VERSION ""

NS_ :

BS_:

BU_: XXX

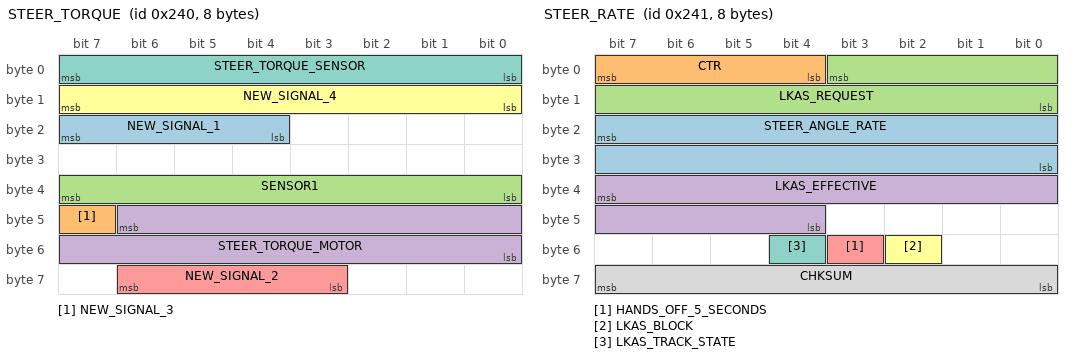
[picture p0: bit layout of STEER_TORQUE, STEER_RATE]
BO_ 576 STEER_TORQUE: 8 XXX
 SG_ NEW_SIGNAL_1 : 23|4@0+ (1,0) [0|255] "" XXX
 SG_ NEW_SIGNAL_3 : 47|1@0+ (1,0) [0|1] "" XXX
 SG_ SENSOR1 : 39|8@0+ (1,-128) [0|127] "" XXX
 SG_ STEER_TORQUE_MOTOR : 46|15@0- (0.1,0) [-3000|3000] "tbd" XXX
 SG_ NEW_SIGNAL_2 : 62|4@0+ (1,0) [0|31] "" XXX
 SG_ NEW_SIGNAL_4 : 15|8@0+ (1,0) [0|127] "" XXX
 SG_ STEER_TORQUE_SENSOR : 7|8@0+ (1,-127) [-85|85] "" XXX

BO_ 577 STEER_RATE: 8 XXX
 SG_ STEER_ANGLE_RATE : 23|16@0+ (0.25,-8192) [0|1] "deg/s" XXX
 SG_ CTR : 7|4@0+ (1,0) [0|15] "" XXX
 SG_ LKAS_REQUEST : 3|12@0+ (1,-2048) [0|15] "" XXX
 SG_ LKAS_EFFECTIVE : 39|12@0+ (1,-2048) [0|255] "" XXX
 SG_ HANDS_OFF_5_SECONDS : 51|1@0+ (1,0) [0|1] "" XXX
 SG_ LKAS_BLOCK : 50|1@1+ (1,0) [0|3] "" XXX
 SG_ LKAS_TRACK_STATE : 52|1@0+ (1,0) [0|3] "" XXX
 SG_ CHKSUM : 63|8@0+ (1,0) [0|255] "" XXX

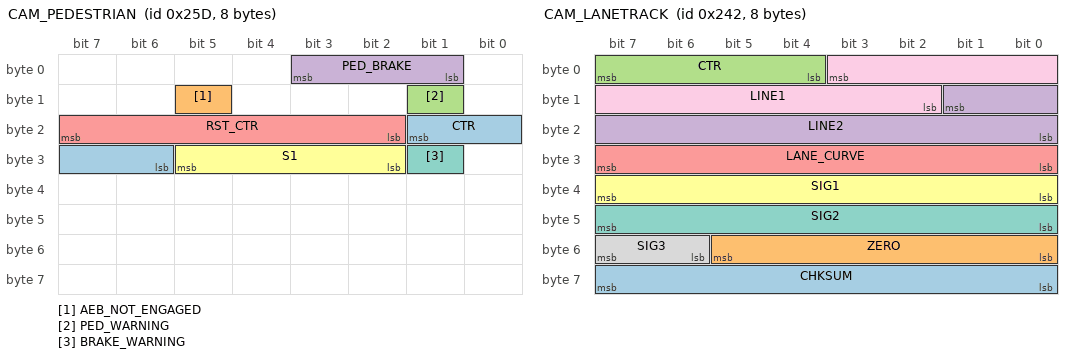
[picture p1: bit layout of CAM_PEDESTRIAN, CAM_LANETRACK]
BO_ 605 CAM_PEDESTRIAN: 8 XXX
 SG_ CTR : 17|4@0+ (1,0) [0|255] "" XXX
 SG_ AEB_NOT_ENGAGED : 13|1@0+ (1,0) [0|1] "" XXX
 SG_ PED_WARNING : 9|1@0+ (1,0) [0|255] "" XXX
 SG_ PED_BRAKE : 3|3@0+ (1,0) [0|7] "" XXX
 SG_ RST_CTR : 23|6@0+ (1,0) [0|63] "" XXX
 SG_ S1 : 29|4@0+ (1,0) [0|31] "" XXX
 SG_ BRAKE_WARNING : 25|1@0+ (1,0) [0|1] "" XXX

BO_ 578 CAM_LANETRACK: 8 XXX
 SG_ CHKSUM : 63|8@0+ (1,0) [0|255] "" XXX
 SG_ ZERO : 53|6@0+ (1,0) [0|63] "" XXX
 SG_ CTR : 7|4@0+ (1,0) [0|15] "" XXX
 SG_ LINE2 : 9|10@0+ (1,-686) [0|255] "" XXX
 SG_ LANE_CURVE : 31|8@0+ (1,-127) [0|255] "" XXX
 SG_ SIG1 : 39|8@0+ (1,-128) [0|255] "" XXX
 SG_ SIG2 : 47|8@0+ (1,0) [0|255] "" XXX
 SG_ SIG3 : 55|2@0+ (1,0) [0|3] "" XXX
 SG_ LINE1 : 3|10@0+ (1,-686) [0|1] "" XXX

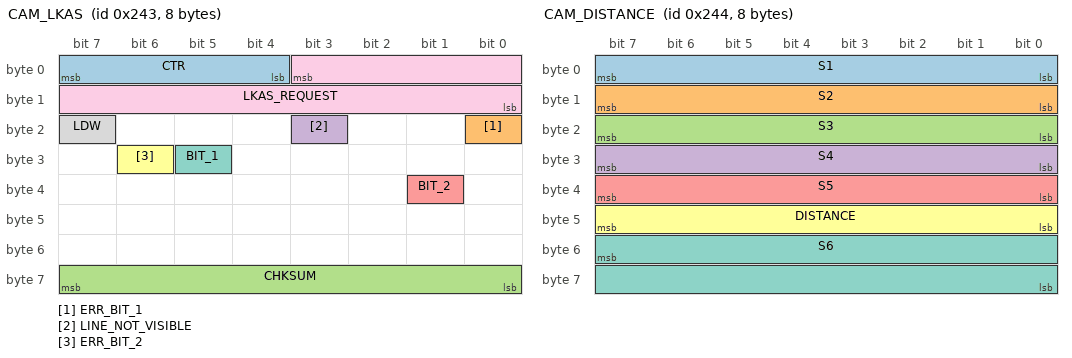
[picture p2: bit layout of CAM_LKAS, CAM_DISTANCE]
BO_ 579 CAM_LKAS: 8 XXX
 SG_ CTR : 7|4@0+ (1,0) [0|15] "" XXX
 SG_ ERR_BIT_1 : 16|1@0+ (1,0) [0|1] "" XXX
 SG_ CHKSUM : 63|8@0+ (1,0) [0|15] "" XXX
 SG_ LINE_NOT_VISIBLE : 19|1@0+ (1,0) [0|1] "" XXX
 SG_ BIT_2 : 33|1@0+ (1,0) [0|1] "" XXX
 SG_ ERR_BIT_2 : 30|1@0+ (1,0) [0|1] "" XXX
 SG_ BIT_1 : 29|1@0+ (1,0) [0|1] "" XXX
 SG_ LDW : 23|1@0+ (1,0) [0|1] "" XXX
 SG_ LKAS_REQUEST : 3|12@0+ (1,-2048) [0|2048] "" XXX

BO_ 580 CAM_DISTANCE: 8 XXX
 SG_ S1 : 0|8@1+ (1,0) [0|127] "" XXX
 SG_ S2 : 15|8@0+ (1,0) [0|1] "" XXX
 SG_ S3 : 16|8@1+ (1,0) [0|3] "" XXX
 SG_ S4 : 24|8@1+ (1,0) [0|31] "" XXX
 SG_ S5 : 32|8@1+ (1,0) [0|255] "" XXX
 SG_ DISTANCE : 47|8@0+ (1,0) [0|65535] "" XXX
 SG_ S6 : 55|16@0+ (1,0) [0|255] "" XXX

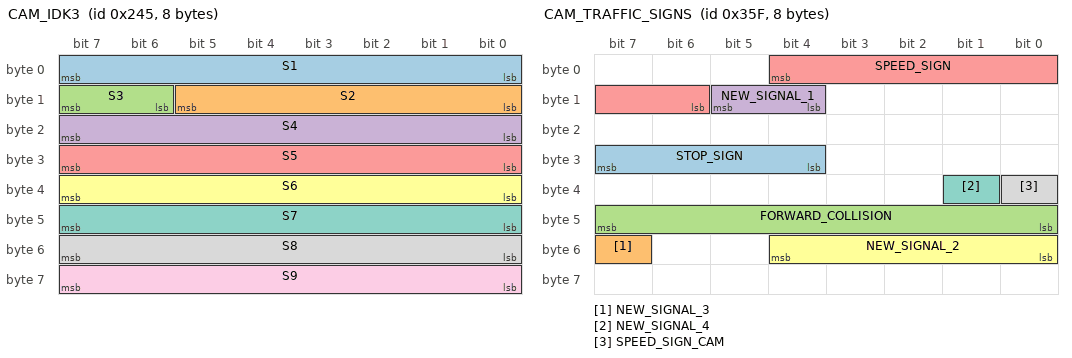
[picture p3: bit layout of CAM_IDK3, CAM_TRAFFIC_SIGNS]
BO_ 581 CAM_IDK3: 8 XXX
 SG_ S1 : 0|8@1+ (1,0) [0|15] "" XXX
 SG_ S2 : 8|6@1+ (1,0) [0|255] "" XXX
 SG_ S3 : 15|2@0+ (1,0) [0|3] "" XXX
 SG_ S4 : 16|8@1+ (1,0) [0|15] "" XXX
 SG_ S5 : 24|8@1+ (1,0) [0|255] "" XXX
 SG_ S6 : 32|8@1+ (1,0) [0|255] "" XXX
 SG_ S7 : 40|8@1+ (1,0) [0|3] "" XXX
 SG_ S8 : 48|8@1+ (1,0) [0|255] "" XXX
 SG_ S9 : 56|8@1+ (1,0) [0|255] "" XXX

BO_ 863 CAM_TRAFFIC_SIGNS: 8 XXX
 SG_ STOP_SIGN : 31|4@0+ (1,0) [0|1] "" XXX
 SG_ NEW_SIGNAL_3 : 55|1@0+ (1,0) [0|127] "" XXX
 SG_ FORWARD_COLLISION : 40|8@1+ (1,0) [0|7] "" XXX
 SG_ NEW_SIGNAL_1 : 13|2@0+ (1,0) [0|3] "" XXX
 SG_ SPEED_SIGN : 4|7@0+ (1,0) [0|15] "" XXX
 SG_ NEW_SIGNAL_2 : 52|5@0+ (1,0) [0|31] "" XXX
 SG_ NEW_SIGNAL_4 : 33|1@0+ (1,0) [0|1] "" XXX
 SG_ SPEED_SIGN_CAM : 32|1@0+ (1,0) [0|32767] "" XXX

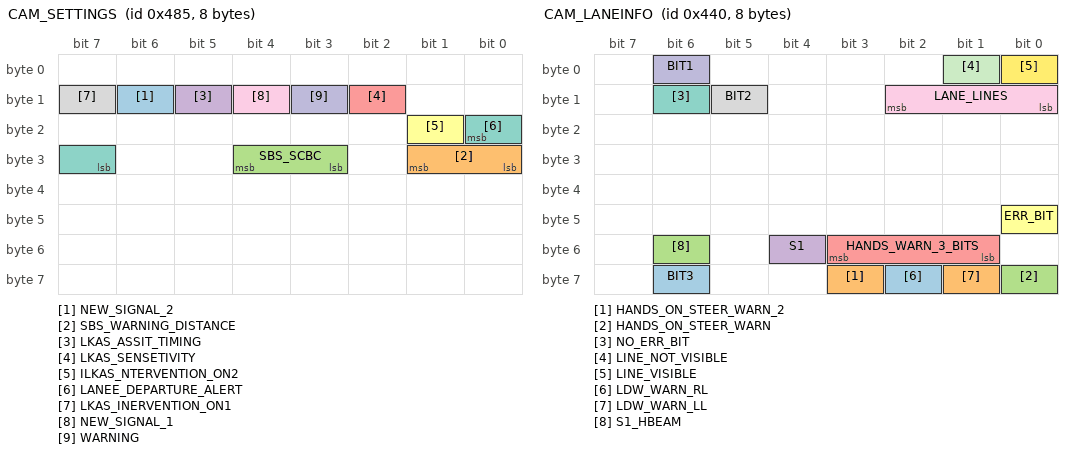
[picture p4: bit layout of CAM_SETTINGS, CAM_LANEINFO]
BO_ 1157 CAM_SETTINGS: 8 XXX
 SG_ NEW_SIGNAL_2 : 14|1@0+ (1,0) [0|1] "" XXX
 SG_ SBS_WARNING_DISTANCE : 25|2@0+ (1,0) [0|127] "" XXX
 SG_ SBS_SCBC : 28|2@0+ (1,0) [0|7] "" XXX
 SG_ LKAS_ASSIT_TIMING : 13|1@0+ (1,0) [0|1] "" XXX
 SG_ LKAS_SENSETIVITY : 10|1@0+ (1,0) [0|1] "" XXX
 SG_ ILKAS_NTERVENTION_ON2 : 17|1@0+ (1,0) [0|255] "" XXX
 SG_ LANEE_DEPARTURE_ALERT : 16|2@0+ (1,0) [0|1] "" XXX
 SG_ LKAS_INERVENTION_ON1 : 15|1@0+ (1,0) [0|1] "" XXX
 SG_ NEW_SIGNAL_1 : 12|1@0+ (1,0) [0|7] "" XXX
 SG_ WARNING : 11|1@0+ (1,0) [0|1] "" XXX

BO_ 1160 CAM_Empty3: 8 XXX
 SG_ NEW_SIGNAL_1 : 47|24@0+ (1,0) [0|16777215] "" XXX

BO_ 1088 CAM_LANEINFO: 8 XXX
 SG_ BIT3 : 62|1@0+ (1,0) [0|3] "" XXX
 SG_ HANDS_ON_STEER_WARN_2 : 59|1@0+ (1,0) [0|1] "" XXX
 SG_ HANDS_ON_STEER_WARN : 56|1@0+ (1,0) [0|3] "" XXX
 SG_ S1 : 52|1@0+ (1,0) [0|1] "" XXX
 SG_ HANDS_WARN_3_BITS : 51|3@0+ (1,0) [0|7] "" XXX
 SG_ ERR_BIT : 40|1@0+ (1,0) [0|1] "" XXX
 SG_ NO_ERR_BIT : 14|1@0+ (1,0) [0|1] "" XXX
 SG_ BIT2 : 13|1@0+ (1,0) [0|15] "" XXX
 SG_ LANE_LINES : 10|3@0+ (1,0) [0|3] "" XXX
 SG_ BIT1 : 6|1@0+ (1,0) [0|65535] "" XXX
 SG_ LINE_NOT_VISIBLE : 1|1@0+ (1,0) [0|1] "" XXX
 SG_ LINE_VISIBLE : 0|1@0+ (1,0) [0|3] "" XXX
 SG_ LDW_WARN_RL : 58|1@0+ (1,0) [0|1] "" XXX
 SG_ LDW_WARN_LL : 57|1@0+ (1,0) [0|1] "" XXX
 SG_ S1_HBEAM : 54|1@0+ (1,0) [0|31] "" XXX

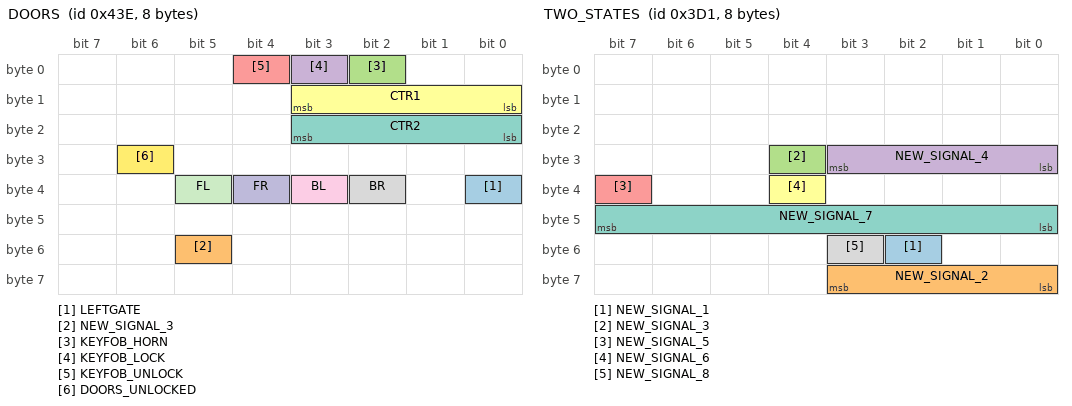
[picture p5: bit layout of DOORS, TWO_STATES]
BO_ 1086 DOORS: 8 XXX
 SG_ LEFTGATE : 32|1@0+ (1,0) [0|1] "" XXX
 SG_ NEW_SIGNAL_3 : 53|1@0+ (1,0) [0|255] "" XXX
 SG_ KEYFOB_HORN : 2|1@0+ (1,0) [0|1] "" XXX
 SG_ KEYFOB_LOCK : 3|1@0+ (1,0) [0|1] "" XXX
 SG_ KEYFOB_UNLOCK : 4|1@0+ (1,0) [0|1] "" XXX
 SG_ CTR1 : 8|4@1+ (1,0) [0|3] "" XXX
 SG_ CTR2 : 16|4@1+ (1,0) [0|15] "" XXX
 SG_ BR : 34|1@0+ (1,0) [0|1] "" XXX
 SG_ BL : 35|1@0+ (1,0) [0|1] "" XXX
 SG_ FR : 36|1@0+ (1,0) [0|1] "" XXX
 SG_ FL : 37|1@0+ (1,0) [0|255] "" XXX
 SG_ DOORS_UNLOCKED : 30|1@0+ (1,0) [0|255] "" XXX

BO_ 977 TWO_STATES: 8 XXX
 SG_ NEW_SIGNAL_1 : 50|1@1+ (1,0) [0|7] "" XXX
 SG_ NEW_SIGNAL_2 : 56|4@1+ (1,0) [0|7] "" XXX
 SG_ NEW_SIGNAL_3 : 28|1@0+ (1,0) [0|255] "" XXX
 SG_ NEW_SIGNAL_4 : 24|4@1+ (1,0) [0|3] "" XXX
 SG_ NEW_SIGNAL_5 : 39|1@0+ (1,0) [0|1] "" XXX
 SG_ NEW_SIGNAL_6 : 36|1@0+ (1,0) [0|1] "" XXX
 SG_ NEW_SIGNAL_7 : 47|8@0+ (1,0) [0|1] "" XXX
 SG_ NEW_SIGNAL_8 : 51|1@0+ (1,0) [0|1] "" XXX

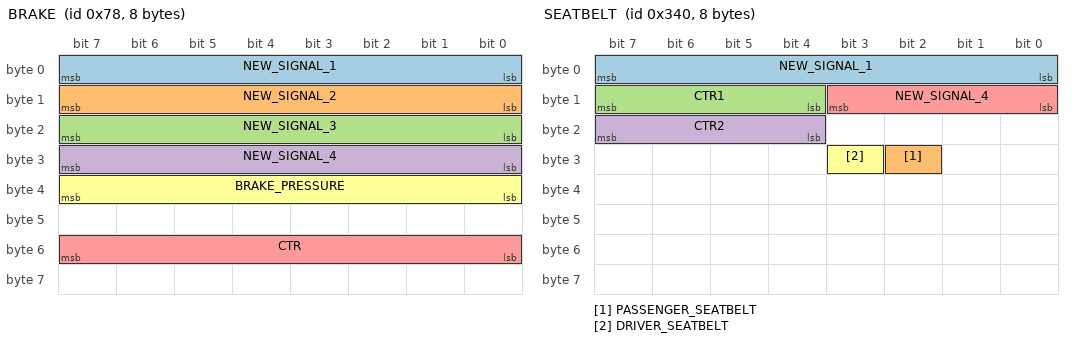
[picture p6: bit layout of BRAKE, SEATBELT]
BO_ 120 BRAKE: 8 XXX
 SG_ NEW_SIGNAL_1 : 7|8@0+ (1,0) [0|255] "" XXX
 SG_ NEW_SIGNAL_2 : 15|8@0+ (1,0) [0|255] "" XXX
 SG_ NEW_SIGNAL_3 : 23|8@0+ (1,0) [0|255] "" XXX
 SG_ NEW_SIGNAL_4 : 31|8@0+ (1,0) [0|255] "" XXX
 SG_ CTR : 55|8@0+ (1,0) [0|255] "" XXX
 SG_ BRAKE_PRESSURE : 39|8@0+ (1,0) [0|255] "" XXX

BO_ 304 GEAR_RELATED: 8 XXX
 SG_ NEW_SIGNAL_1 : 55|8@0+ (1,0) [0|255] "" XXX
 SG_ NEW_SIGNAL_2 : 47|8@0+ (1,0) [0|255] "" XXX

BO_ 832 SEATBELT: 8 XXX
 SG_ NEW_SIGNAL_1 : 7|8@0+ (1,0) [0|255] "" XXX
 SG_ PASSENGER_SEATBELT : 26|1@1+ (1,0) [0|7] "" XXX
 SG_ CTR1 : 15|4@0+ (1,0) [0|15] "" XXX
 SG_ CTR2 : 23|4@0+ (1,0) [0|255] "" XXX
 SG_ NEW_SIGNAL_4 : 8|4@1+ (1,0) [0|3] "" XXX
 SG_ DRIVER_SEATBELT : 27|1@0+ (1,0) [0|1] "" XXX

BO_ 157 CRZ_BTNS: 8 XXX
 SG_ SET_P_INV : 21|1@0+ (1,0) [0|3] "" XXX
 SG_ CAN_OFF_INV : 17|1@1+ (1,0) [0|3] "" XXX
 SG_ CAN_OFF : 0|1@1+ (1,0) [0|3] "" XXX
 SG_ SET_M_INV : 22|1@0+ (1,0) [0|255] "" XXX
 SG_ SET_M : 5|1@0+ (1,0) [0|3] "" XXX
 SG_ SET_P : 4|1@0+ (1,0) [0|3] "" XXX
 SG_ RES_INV : 19|1@1+ (1,0) [0|3] "" XXX
 SG_ RES : 2|1@1+ (1,0) [0|3] "" XXX
 SG_ DISTANCE_LESS : 7|1@0+ (1,0) [0|1] "" XXX
 SG_ DISTANCE_LESS_INV : 8|1@0+ (1,0) [0|31] "" XXX
 SG_ DISTANCE_MORE : 6|1@0+ (1,0) [0|3] "" XXX
 SG_ DISTANCE_MORE_INV : 23|1@0+ (1,0) [0|1] "" XXX
 SG_ MODE_Y : 13|1@1+ (1,0) [0|3] "" XXX
 SG_ MODE_X : 14|1@0+ (1,0) [0|255] "" XXX
 SG_ MODE_Y_INV : 30|1@0+ (1,0) [0|3] "" XXX
 SG_ MODE_X_INV : 31|1@0+ (1,0) [0|3] "" XXX
 SG_ CTR : 29|4@0+ (1,0) [0|255] "" XXX

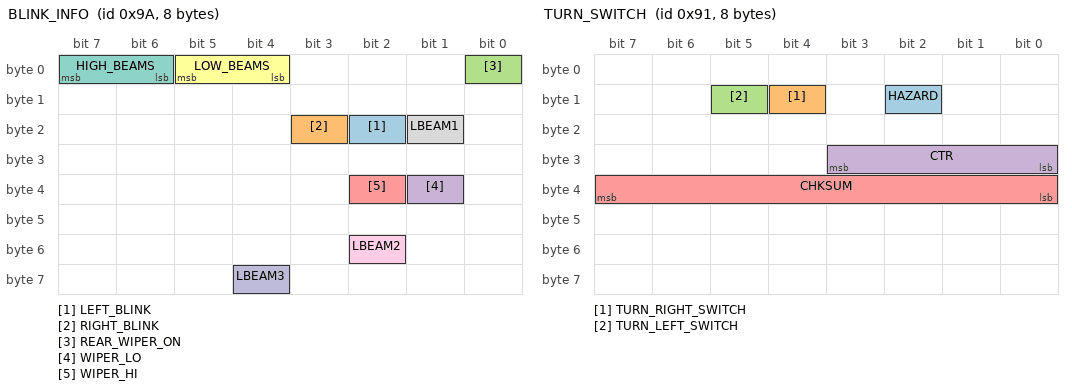
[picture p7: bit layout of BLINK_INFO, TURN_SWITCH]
BO_ 154 BLINK_INFO: 8 XXX
 SG_ LEFT_BLINK : 18|1@1+ (1,0) [0|3] "" XXX
 SG_ RIGHT_BLINK : 19|1@0+ (1,0) [0|255] "" XXX
 SG_ REAR_WIPER_ON : 0|1@0+ (1,0) [0|1] "" XXX
 SG_ WIPER_LO : 33|1@1+ (1,0) [0|31] "" XXX
 SG_ WIPER_HI : 34|1@0+ (1,0) [0|1] "" XXX
 SG_ LOW_BEAMS : 5|2@0+ (1,0) [0|3] "" XXX
 SG_ HIGH_BEAMS : 7|2@0+ (1,0) [0|3] "" XXX
 SG_ LBEAM1 : 17|1@0+ (1,0) [0|1] "" XXX
 SG_ LBEAM2 : 50|1@0+ (1,0) [0|1] "" XXX
 SG_ LBEAM3 : 60|1@0+ (1,0) [0|1] "" XXX

BO_ 145 TURN_SWITCH: 8 XXX
 SG_ HAZARD : 10|1@0+ (1,0) [0|1] "" XXX
 SG_ TURN_RIGHT_SWITCH : 12|1@0+ (1,0) [0|3] "" XXX
 SG_ TURN_LEFT_SWITCH : 13|1@0+ (1,0) [0|255] "" XXX
 SG_ CTR : 27|4@0+ (1,0) [0|255] "" XXX
 SG_ CHKSUM : 39|8@0+ (1,0) [0|15] "" XXX

BO_ 606 SPEED_TBD: 8 XXX
 SG_ SPEED_TBD : 7|12@0+ (1,0) [0|255] "" XXX
 SG_ NEW_SIGNAL_1 : 23|12@0- (1,0) [0|65535] "" XXX

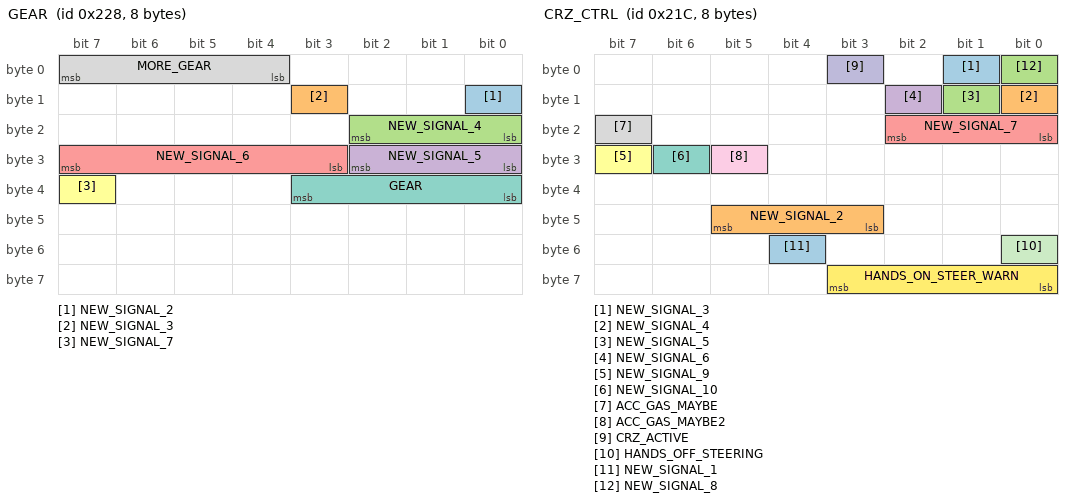
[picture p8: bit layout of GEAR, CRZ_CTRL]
BO_ 552 GEAR: 8 XXX
 SG_ NEW_SIGNAL_2 : 8|1@0+ (1,0) [0|255] "" XXX
 SG_ NEW_SIGNAL_3 : 11|1@0+ (1,0) [0|1] "" XXX
 SG_ NEW_SIGNAL_4 : 18|3@0+ (1,0) [0|255] "" XXX
 SG_ NEW_SIGNAL_5 : 26|3@0+ (1,0) [0|255] "" XXX
 SG_ NEW_SIGNAL_6 : 31|5@0+ (1,0) [0|31] "" XXX
 SG_ NEW_SIGNAL_7 : 39|1@0+ (1,0) [0|255] "" XXX
 SG_ GEAR : 35|4@0+ (1,0) [0|15] "" XXX
 SG_ MORE_GEAR : 7|4@0+ (1,0) [0|255] "" XXX

BO_ 543 CRZ_EVENTS: 8 XXX
 SG_ NEW_SIGNAL_3 : 34|1@0+ (1,0) [0|1] "" XXX
 SG_ CHKSUM : 63|8@0+ (1,0) [0|15] "" XXX
 SG_ NEW_SIGNAL_1 : 55|4@0+ (1,0) [0|15] "" XXX
 SG_ NEW_SIGNAL_5 : 47|4@0+ (1,0) [0|15] "" XXX
 SG_ NEW_SIGNAL_6 : 6|1@0+ (1,0) [0|255] "" XXX
 SG_ NEW_SIGNAL_8 : 0|1@0+ (1,0) [0|31] "" XXX
 SG_ NEW_SIGNAL_9 : 1|1@0+ (1,0) [0|1] "" XXX
 SG_ NEW_SIGNAL_10 : 2|1@0+ (1,0) [0|1] "" XXX
 SG_ NEW_SIGNAL_12 : 10|1@0+ (1,0) [0|1] "" XXX
 SG_ NEW_SIGNAL_13 : 9|1@0+ (1,0) [0|1] "" XXX
 SG_ NEW_SIGNAL_18 : 12|1@0+ (1,0) [0|15] "" XXX
 SG_ NEW_SIGNAL_19 : 14|1@0+ (1,0) [0|1] "" XXX
 SG_ NEW_SIGNAL_20 : 15|1@0+ (1,0) [0|1] "" XXX
 SG_ NEW_SIGNAL_21 : 23|1@0+ (1,0) [0|15] "" XXX
 SG_ NEW_SIGNAL_24 : 31|1@0+ (1,0) [0|1] "" XXX
 SG_ GAS_PEDAL_PRESSED : 32|1@0+ (1,0) [0|255] "" XXX
 SG_ CRZ_STARTED : 18|1@0+ (1,0) [0|1] "" XXX
 SG_ PLUS_ONE_CRZ : 17|1@0+ (1,0) [0|255] "" XXX
 SG_ PLUS_ONE_CRZ_2 : 19|1@0+ (1,0) [0|1] "" XXX
 SG_ GAS_MAYBE : 22|1@0+ (1,0) [0|1] "" XXX
 SG_ NONACC_ACTIVE : 5|1@0+ (1,0) [0|1] "" XXX
 SG_ CRUISE_ACTIVE_CAR_MOVING : 16|1@0+ (1,0) [0|1] "" XXX
 SG_ NONACC_RELATED : 11|1@0+ (1,0) [0|255] "" XXX
 SG_ CTR : 51|4@0+ (1,0) [0|15] "" XXX
 SG_ CAS_CMD_MAYBE : 30|7@0- (1,0) [0|255] "" XXX
 SG_ NEW_SIGNAL_4 : 43|4@0+ (1,0) [0|255] "" XXX

BO_ 535 CURVE_CTRS: 8 XXX
 SG_ CTR_A_1 : 4|3@0+ (1,0) [0|31] "" XXX
 SG_ CTR_A_2 : 7|3@0+ (1,0) [0|255] "" XXX
 SG_ CTR_B_1 : 12|3@0+ (1,0) [0|7] "" XXX
 SG_ CTR_B_2 : 15|3@0+ (1,0) [0|7] "" XXX
 SG_ CTR_C_1 : 20|3@0+ (1,0) [0|7] "" XXX
 SG_ CTR_C_2 : 23|3@0+ (1,0) [0|255] "" XXX
 SG_ CTR_D_1 : 28|3@0+ (1,0) [0|7] "" XXX
 SG_ CHK_MAYBE : 63|8@0+ (1,0) [0|255] "" XXX
 SG_ NEW_SIGNAL_1 : 0|1@0+ (1,0) [0|1] "" XXX
 SG_ NEW_SIGNAL_2 : 1|1@0+ (1,0) [0|1] "" XXX
 SG_ NEW_SIGNAL_6 : 17|1@0+ (1,0) [0|1] "" XXX
 SG_ NEW_SIGNAL_7 : 24|1@0+ (1,0) [0|1] "" XXX
 SG_ NEW_SIGNAL_8 : 25|1@0+ (1,0) [0|1] "" XXX
 SG_ SEATBELT_MAYBE : 8|1@0+ (1,0) [0|1] "" XXX
 SG_ NO_SEATBELT_MAYBE : 16|1@0+ (1,0) [0|1] "" XXX
 SG_ NEW_SIGNAL_4 : 9|1@0+ (1,0) [0|1] "" XXX
 SG_ CTR_D_2 : 31|3@0+ (1,0) [0|7] "" XXX
 SG_ CTR : 55|8@0+ (1,0) [0|255] "" XXX
 SG_ Speed : 39|16@0+ (0.01,0) [0|7] "kph" XXX

BO_ 540 CRZ_CTRL: 8 XXX
 SG_ NEW_SIGNAL_3 : 1|1@0+ (1,0) [0|1] "" XXX
 SG_ NEW_SIGNAL_4 : 8|1@0+ (1,0) [0|255] "" XXX
 SG_ NEW_SIGNAL_5 : 9|1@0+ (1,0) [0|1] "" XXX
 SG_ NEW_SIGNAL_6 : 10|1@0+ (1,0) [0|1] "" XXX
 SG_ NEW_SIGNAL_7 : 18|3@0+ (1,0) [0|255] "" XXX
 SG_ NEW_SIGNAL_9 : 31|1@0+ (1,0) [0|255] "" XXX
 SG_ NEW_SIGNAL_10 : 30|1@0+ (1,0) [0|1] "" XXX
 SG_ ACC_GAS_MAYBE : 23|1@0+ (1,0) [0|31] "" XXX
 SG_ ACC_GAS_MAYBE2 : 29|1@0+ (1,0) [0|1] "" XXX
 SG_ CRZ_ACTIVE : 3|1@0+ (1,0) [0|1] "" XXX
 SG_ HANDS_OFF_STEERING : 48|1@0+ (1,0) [0|1] "" XXX
 SG_ HANDS_ON_STEER_WARN : 59|4@0+ (1,0) [0|255] "" XXX
 SG_ NEW_SIGNAL_1 : 52|1@0+ (1,0) [0|1] "" XXX
 SG_ NEW_SIGNAL_2 : 45|3@0+ (1,0) [0|255] "" XXX
 SG_ NEW_SIGNAL_8 : 0|1@0+ (1,0) [0|1] "" XXX

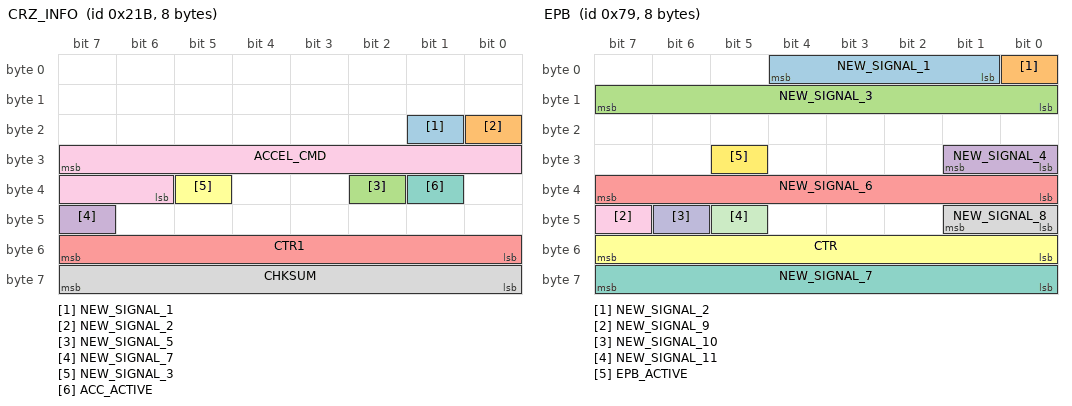
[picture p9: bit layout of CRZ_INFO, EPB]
BO_ 539 CRZ_INFO: 8 XXX
 SG_ NEW_SIGNAL_1 : 17|1@0+ (1,0) [0|255] "" XXX
 SG_ NEW_SIGNAL_2 : 16|1@0+ (1,0) [0|1] "" XXX
 SG_ NEW_SIGNAL_5 : 34|1@0+ (1,0) [0|1] "" XXX
 SG_ NEW_SIGNAL_7 : 47|1@0+ (1,0) [0|255] "" XXX
 SG_ CTR1 : 55|8@0+ (1,0) [0|255] "" XXX
 SG_ NEW_SIGNAL_3 : 37|1@0+ (1,0) [0|255] "" XXX
 SG_ ACC_ACTIVE : 33|1@0+ (1,0) [0|1] "" XXX
 SG_ CHKSUM : 63|8@0+ (1,0) [0|255] "" XXX
 SG_ ACCEL_CMD : 31|10@0- (1,0) [0|1] "" XXX

BO_ 121 EPB: 8 XXX
 SG_ NEW_SIGNAL_1 : 4|4@0+ (1,0) [0|255] "" XXX
 SG_ NEW_SIGNAL_2 : 0|1@0+ (1,0) [0|1] "" XXX
 SG_ NEW_SIGNAL_3 : 15|8@0+ (1,0) [0|255] "" XXX
 SG_ NEW_SIGNAL_4 : 25|2@0+ (1,0) [0|255] "" XXX
 SG_ NEW_SIGNAL_6 : 39|8@0+ (1,0) [0|255] "" XXX
 SG_ CTR : 55|8@0+ (1,0) [0|255] "" XXX
 SG_ NEW_SIGNAL_7 : 63|8@0+ (1,0) [0|255] "" XXX
 SG_ NEW_SIGNAL_8 : 41|2@0+ (1,0) [0|255] "" XXX
 SG_ NEW_SIGNAL_9 : 47|1@0+ (1,0) [0|63] "" XXX
 SG_ NEW_SIGNAL_10 : 46|1@0+ (1,0) [0|1] "" XXX
 SG_ NEW_SIGNAL_11 : 45|1@0+ (1,0) [0|1] "" XXX
 SG_ EPB_ACTIVE : 29|1@0+ (1,0) [0|15] "" XXX

BO_ 1238 TEMPERATURE: 8 XXX
 SG_ TEMPERATURE_MAYBE : 47|8@0+ (1,0) [0|4294967295] "" XXX

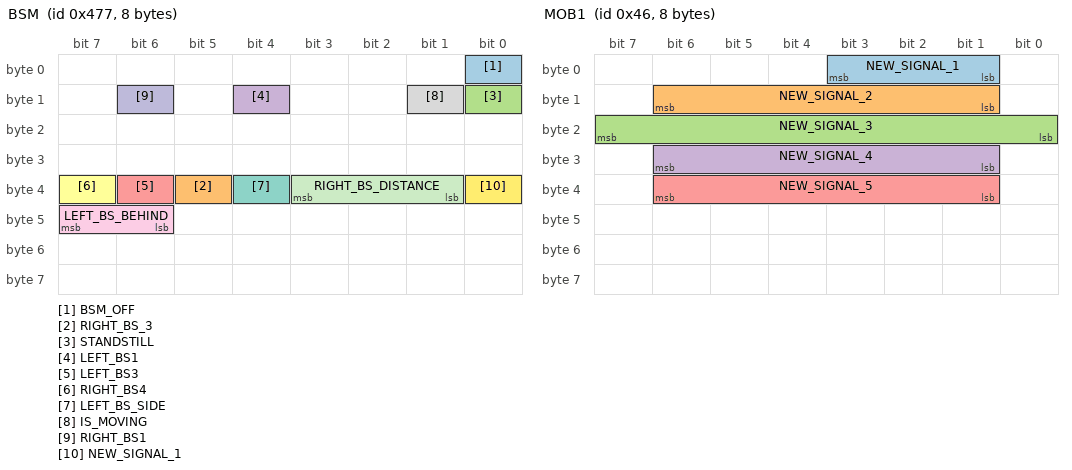
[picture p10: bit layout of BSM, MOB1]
BO_ 1143 BSM: 8 XXX
 SG_ BSM_OFF : 0|1@0+ (1,0) [0|1] "" XXX
 SG_ RIGHT_BS_3 : 37|1@0+ (1,0) [0|1] "" XXX
 SG_ STANDSTILL : 8|1@0+ (1,0) [0|1] "" XXX
 SG_ LEFT_BS1 : 12|1@0+ (1,0) [0|1] "" XXX
 SG_ LEFT_BS3 : 38|1@0+ (1,0) [0|1] "" XXX
 SG_ RIGHT_BS4 : 39|1@0+ (1,0) [0|1] "" XXX
 SG_ LEFT_BS_SIDE : 36|1@0+ (1,0) [0|1] "" XXX
 SG_ IS_MOVING : 9|1@0+ (1,0) [0|1] "" XXX
 SG_ LEFT_BS_BEHIND : 46|2@1+ (1,0) [0|16777215] "" XXX
 SG_ RIGHT_BS1 : 14|1@0+ (1,0) [0|63] "" XXX
 SG_ RIGHT_BS_DISTANCE : 35|3@0+ (1,0) [0|1] "" XXX
 SG_ NEW_SIGNAL_1 : 32|1@0+ (1,0) [0|1] "" XXX

BO_ 1361 KEY_POSITION: 8 XXX

BO_ 1283 KEY_POSITION2: 8 XXX

BO_ 70 MOB1: 8 XXX
 SG_ NEW_SIGNAL_1 : 1|3@1+ (1,0) [0|15] "" XXX
 SG_ NEW_SIGNAL_2 : 14|6@0+ (1,0) [0|127] "" XXX
 SG_ NEW_SIGNAL_3 : 23|8@0+ (1,0) [0|255] "" XXX
 SG_ NEW_SIGNAL_4 : 30|6@0+ (1,0) [0|255] "" XXX
 SG_ NEW_SIGNAL_5 : 38|6@0+ (1,0) [0|7] "" XXX

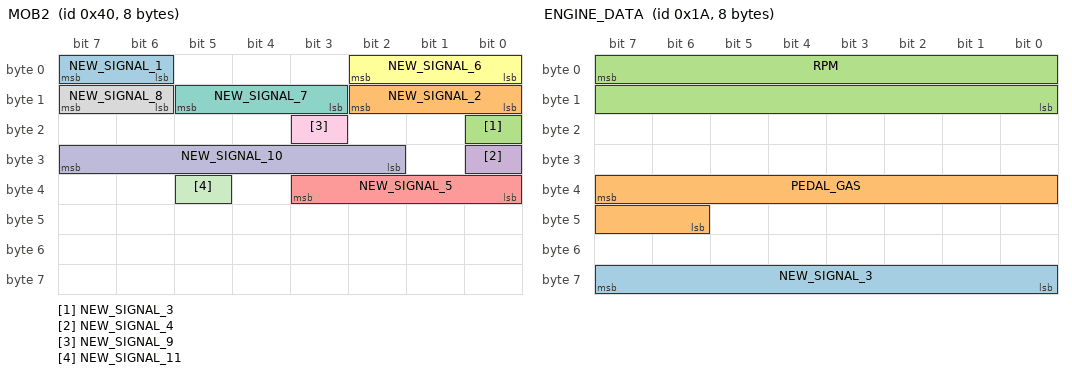
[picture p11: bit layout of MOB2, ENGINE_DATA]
BO_ 64 MOB2: 8 XXX
 SG_ NEW_SIGNAL_1 : 7|2@0+ (1,0) [0|255] "" XXX
 SG_ NEW_SIGNAL_2 : 10|3@0+ (1,0) [0|255] "" XXX
 SG_ NEW_SIGNAL_3 : 16|1@0+ (1,0) [0|255] "" XXX
 SG_ NEW_SIGNAL_4 : 24|1@0+ (1,0) [0|255] "" XXX
 SG_ NEW_SIGNAL_5 : 35|4@0+ (1,0) [0|255] "" XXX
 SG_ NEW_SIGNAL_6 : 0|3@1+ (1,0) [0|7] "" XXX
 SG_ NEW_SIGNAL_7 : 13|3@0+ (1,0) [0|3] "" XXX
 SG_ NEW_SIGNAL_8 : 15|2@0+ (1,0) [0|3] "" XXX
 SG_ NEW_SIGNAL_9 : 19|1@0+ (1,0) [0|1] "" XXX
 SG_ NEW_SIGNAL_10 : 31|6@0+ (1,0) [0|3] "" XXX
 SG_ NEW_SIGNAL_11 : 37|1@0+ (1,0) [0|1] "" XXX

BO_ 1171 MOB3: 8 XXX

BO_ 1248 MOB4: 8 XXX

BO_ 26 ENGINE_DATA: 8 XXX
 SG_ NEW_SIGNAL_3 : 63|8@0+ (1,0) [0|65535] "" XXX
 SG_ PEDAL_GAS : 39|10@0+ (1,0) [0|65535] "" XXX
 SG_ RPM : 7|16@0+ (1,0) [0|65535] "" XXX

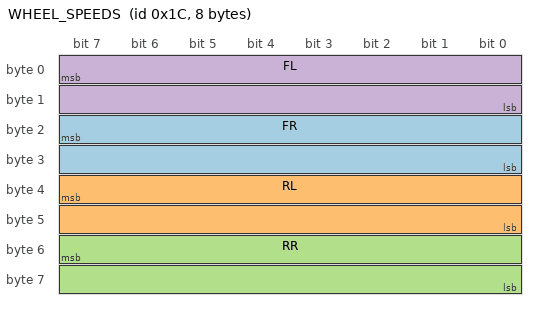
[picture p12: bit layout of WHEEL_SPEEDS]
BO_ 28 WHEEL_SPEEDS: 8 XXX
 SG_ FR : 23|16@0+ (0.01,-100) [0|65535] "" XXX
 SG_ RL : 39|16@0+ (0.01,-100) [0|65535] "" XXX
 SG_ RR : 55|16@0+ (0.01,-100) [0|65535] "" XXX
 SG_ FL : 7|16@0+ (0.01,-100) [0|65535] "" XXX

BO_ 59 STEER: 8 XXX
 SG_ NEW_SIGNAL_2 : 55|16@0+ (1,0) [0|65535] "" XXX
 SG_ STEER_ANGLE : 23|16@0+ (0.05,-1600) [0|65535] "" XXX

CM_ SG_ 605 PED_BRAKE "3: no brake, 4: brake";
CM_ SG_ 605 BRAKE_WARNING "Flashing brake warning and audible alert for potential forward collision";
CM_ SG_ 863 SPEED_SIGN "speed limit in MPH";
CM_ SG_ 863 SPEED_SIGN_CAM "1: The speed limit is recognized by the camera. 0: speed limit is map based or is not available";
CM_ SG_ 1157 SBS_WARNING_DISTANCE "1 far, 2 mid, 3 near";
CM_ SG_ 1157 SBS_SCBC "1 off, 2 on";
CM_ SG_ 1157 LKAS_ASSIT_TIMING "1 at, 0 before";
CM_ SG_ 1157 LKAS_SENSETIVITY "0 low, 1 high";
CM_ SG_ 1157 LANEE_DEPARTURE_ALERT "1 off, 2 on";
CM_ SG_ 1157 WARNING "1 Rare, 0 often";
CM_ SG_ 1088 LANE_LINES "0 LKAS disabled, 1 no lines, 2 two lines, 3 left line, 4 right line";
CM_ SG_ 1045 ABS_MALFUNCTION "off: 0, solid: 1, slow blink: 2, fast blink: 3";
CM_ SG_ 157 CAN_OFF "Disengage Cruise if enabled, if already disabled  TURN it OFF ";
CM_ SG_ 552 GEAR "0 P/N, 12 R, 2 D M1, 4 M2, 14 Shift";
CM_ SG_ 540 HANDS_ON_STEER_WARN "0 no warning, b warning";
